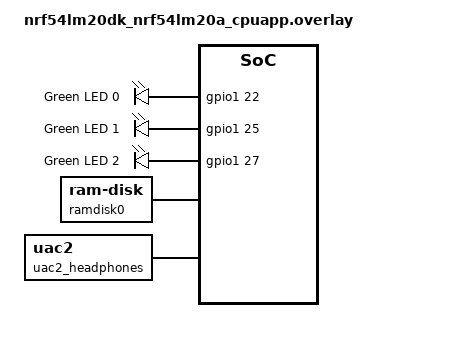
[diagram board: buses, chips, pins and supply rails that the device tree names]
/*
 * Copyright (c) 2024 Nordic Semiconductor ASA
 *
 * SPDX-License-Identifier: LicenseRef-Nordic-5-Clause
 */

 #include <dt-bindings/usb/audio.h>

/ {
	audioleds: audioleds {
		compatible = "gpio-leds";
		status = "okay";

		led_conn_status: led_conn_status {
			gpios = <&gpio1 22 GPIO_ACTIVE_HIGH>;
			label = "Green LED 0";
		};

		led_sync_status: led_sync_status {
			gpios = <&gpio1 25 GPIO_ACTIVE_HIGH>;
			label = "Green LED 1";
		};

		led_app_status: led_app_status {
			gpios = <&gpio1 27 GPIO_ACTIVE_HIGH>;
			label = "Green LED 2";
		};
	};

	ramdisk0: ramdisk0 {
		compatible = "zephyr,ram-disk";
		disk-name = "RAM";
		sector-size = <512>;
		sector-count = <80>;
	};
};

/ {
	uac2_headphones: usb_audio2 {
		compatible = "zephyr,uac2";
		status = "okay";
		full-speed;
		audio-function = <AUDIO_FUNCTION_OTHER>;

		hp_uac_aclk: hp_aclk {
			compatible = "zephyr,uac2-clock-source";
			clock-type = "internal-programmable";
			frequency-control = "host-programmable";
			sampling-frequencies = <48000>;
			sof-synchronized;
		};

		hp_out_terminal: out_terminal {
			compatible = "zephyr,uac2-input-terminal";
			clock-source = <&hp_uac_aclk>;
			terminal-type = <USB_TERMINAL_STREAMING>;
			front-left;
			front-right;
		};

		hp_headphones_output: hp_headphones_output {
			compatible = "zephyr,uac2-output-terminal";
			data-source = <&hp_out_terminal>;
			clock-source = <&hp_uac_aclk>;
			terminal-type = <OUTPUT_TERMINAL_HEADPHONES>;
		};

		hp_as_iso_out: out_interface {
			compatible = "zephyr,uac2-audio-streaming";
			linked-terminal = <&hp_out_terminal>;
			subslot-size = <2>;
			bit-resolution = <16>;
		};
	};
};
